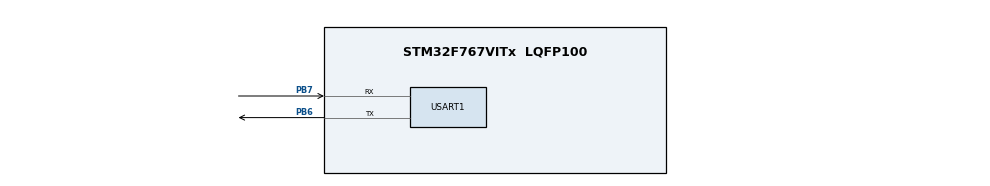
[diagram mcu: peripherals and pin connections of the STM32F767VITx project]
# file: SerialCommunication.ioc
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Dma.Request0=USART1_RX
Dma.Request1=USART1_TX
Dma.USART1_RX.0.Direction=DMA_PERIPH_TO_MEMORY
Dma.USART1_RX.0.FIFOMode=DMA_FIFOMODE_DISABLE
Dma.USART1_RX.0.Instance=DMA2_Stream5
Dma.USART1_RX.0.MemDataAlignment=DMA_MDATAALIGN_BYTE
Dma.USART1_RX.0.MemInc=DMA_MINC_ENABLE
Dma.USART1_RX.0.Mode=DMA_CIRCULAR
Dma.USART1_RX.0.PeriphDataAlignment=DMA_PDATAALIGN_BYTE
Dma.USART1_RX.0.PeriphInc=DMA_PINC_DISABLE
Dma.USART1_RX.0.Priority=DMA_PRIORITY_LOW
Dma.USART1_TX.1.Direction=DMA_MEMORY_TO_PERIPH
Dma.USART1_TX.1.FIFOMode=DMA_FIFOMODE_DISABLE
Dma.USART1_TX.1.Instance=DMA2_Stream7
Dma.USART1_TX.1.MemDataAlignment=DMA_MDATAALIGN_BYTE
Dma.USART1_TX.1.MemInc=DMA_MINC_ENABLE
Dma.USART1_TX.1.Mode=DMA_CIRCULAR
Dma.USART1_TX.1.PeriphDataAlignment=DMA_PDATAALIGN_BYTE
Dma.USART1_TX.1.PeriphInc=DMA_PINC_DISABLE
Dma.USART1_TX.1.Priority=DMA_PRIORITY_LOW
Mcu.Family=STM32F7
Mcu.Name=STM32F767VITx
Mcu.Package=LQFP100
NVIC.DMA2_Stream5_IRQn=true\:5\:0\:true\:false\:true\:false\:true
NVIC.DMA2_Stream7_IRQn=true\:5\:0\:true\:false\:true\:false\:true
NVIC.FLASH_IRQn=true\:5\:0\:true\:false\:true\:true\:true
NVIC.FPU_IRQn=true\:5\:0\:true\:false\:true\:true\:false
NVIC.PVD_IRQn=true\:5\:0\:true\:false\:true\:true\:true
NVIC.PriorityGroup=NVIC_PRIORITYGROUP_4
NVIC.RCC_IRQn=true\:5\:0\:true\:false\:true\:true\:false
NVIC.TIM7_IRQn=true\:0\:0\:true\:false\:true\:false\:true
NVIC.TimeBase=TIM7_IRQn
NVIC.TimeBaseIP=TIM7
NVIC.USART1_IRQn=true\:5\:0\:true\:false\:true\:true\:true
PA13.Mode=Serial_Wire
PA13.Signal=SYS_JTMS-SWDIO
PA14.Mode=Serial_Wire
PA14.Signal=SYS_JTCK-SWCLK
PB6.Mode=Asynchronous
PB6.Signal=USART1_TX
PB7.Mode=Asynchronous
PB7.Signal=USART1_RX
PH0/OSC_IN.Mode=HSE-External-Oscillator
PH0/OSC_IN.Signal=RCC_OSC_IN
PH1/OSC_OUT.Mode=HSE-External-Oscillator
PH1/OSC_OUT.Signal=RCC_OSC_OUT
ProjectManager.HeapSize=0x200
ProjectManager.StackSize=0x400
ProjectManager.TargetToolchain=STM32CubeIDE
RCC.AHBFreq_Value=216000000
RCC.APB1CLKDivider=RCC_HCLK_DIV4
RCC.APB1Freq_Value=54000000
RCC.APB1TimFreq_Value=108000000
RCC.APB2CLKDivider=RCC_HCLK_DIV4
RCC.APB2Freq_Value=54000000
RCC.APB2TimFreq_Value=108000000
RCC.CortexFreq_Value=216000000
RCC.HCLKFreq_Value=216000000
RCC.HSE_VALUE=25000000
RCC.HSI_VALUE=16000000
RCC.LSE_VALUE=32768
RCC.PLLM=25
RCC.PLLN=432
RCC.PLLSourceVirtual=RCC_PLLSOURCE_HSE
RCC.PWREXT_OverDrive=PWREXT_OverDrive_ACTIVATED
RCC.PWR_Regulator_Voltage_Scale=PWR_REGULATOR_VOLTAGE_SCALE1
RCC.SYSCLKFreq_VALUE=216000000
RCC.SYSCLKSource=RCC_SYSCLKSOURCE_PLLCLK
RCC.USBFreq_Value=216000000
RCC.VCOOutputFreq_Value=432000000
USART1.DMADisableonRxErrorParam=ADVFEATURE_DMA_DISABLEONRXERROR
USART1.OverrunDisableParam=ADVFEATURE_OVERRUN_DISABLE
USART1.VirtualMode-Asynchronous=VM_ASYNC
VP_SYS_VS_tim7.Mode=TIM7
board=custom

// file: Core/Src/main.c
/* USER CODE BEGIN Header */
/**
  ******************************************************************************
  * @file           : main.c
  * @brief          : Main program body
  ******************************************************************************
  * @attention
  *
  * <h2><center>&copy; Copyright (c) 2023 STMicroelectronics.
  * All rights reserved.</center></h2>
  *
  * This software component is licensed by ST under BSD 3-Clause license,
  * the "License"; You may not use this file except in compliance with the
  * License. You may obtain a copy of the License at:
  *                        opensource.org/licenses/BSD-3-Clause
  *
  ******************************************************************************
  */
/* USER CODE END Header */
#include "main.h"
#include "dma.h"
#include "usart.h"
#include "gpio.h"

/* USER CODE BEGIN Includes */
#include "mbotLinuxUsart.h"
/* USER CODE END Includes */

/* USER CODE BEGIN PV */
//测试发�?�变�??
// send the uav's position and orierntation to linux
/*double positionX_uav, positionY_uav, positionZ_uav;
double orientationX_uav, orientationY_uav, orientationZ_uav, orientationW_uav;*/

double positionX_uav = 0.4222;
double positionY_uav = 0.4222;
double positionZ_uav = 0.4222;
double orientationX_uav =  0.4222;
double orientationY_uav = 0.4222;
double orientationZ_uav = 0.4222;
double orientationW_uav = 0.5555;

/*short testSend1   =5000;
short testSend2   =2000;
short testSend3   =1000;
unsigned char testSend4 = 0x05;
*/
// receive mocap value,and reserve pose and orientaion in position and orierntation
int positionX_mocap, positionY_mocap, positionZ_nocap;
int orientationX_mocap, orientationY_mocap, orientationZ_mocap, orientationW_mocap;
//测试接收变量
/*
int testRece1     =0;
int testRece2     =0;
unsigned char testRece3 = 0x00;
*/
/* USER CODE END PV */

void SystemClock_Config(void);

int main(void)
{

  /* MCU Configuration--------------------------------------------------------*/

  /* Reset of all peripherals, Initializes the Flash interface and the Systick. */
  HAL_Init();

  /* Configure the system clock */
  SystemClock_Config();

  /* Initialize all configured peripherals */
  MX_GPIO_Init();
  MX_DMA_Init();
  MX_USART1_UART_Init();

  /* Infinite loop */
  while (1)
  {
		//将需要发送到ROS的数据，从该函数发出，前三个数据范围（-32768 - +32767），第四个数据的范围(0 - 255)
		usartSendData( positionX_uav, positionY_uav, positionZ_uav,
    orientationX_uav, orientationY_uav, orientationZ_uav, orientationW_uav);
		//必须的延时
		HAL_Delay(13);
  }
}

void SystemClock_Config(void)
{
  LL_FLASH_SetLatency(LL_FLASH_LATENCY_7);
  while(LL_FLASH_GetLatency()!= LL_FLASH_LATENCY_7)
  {
  }
  LL_PWR_SetRegulVoltageScaling(LL_PWR_REGU_VOLTAGE_SCALE1);
  LL_PWR_EnableOverDriveMode();
  LL_RCC_HSE_Enable();

   /* Wait till HSE is ready */
  while(LL_RCC_HSE_IsReady() != 1)
  {

  }
  LL_RCC_PLL_ConfigDomain_SYS(LL_RCC_PLLSOURCE_HSE, LL_RCC_PLLM_DIV_25, 432, LL_RCC_PLLP_DIV_2);
  LL_RCC_PLL_Enable();

   /* Wait till PLL is ready */
  while(LL_RCC_PLL_IsReady() != 1)
  {

  }
  LL_RCC_SetAHBPrescaler(LL_RCC_SYSCLK_DIV_1);
  LL_RCC_SetAPB1Prescaler(LL_RCC_APB1_DIV_4);
  LL_RCC_SetAPB2Prescaler(LL_RCC_APB2_DIV_4);
  LL_RCC_SetSysClkSource(LL_RCC_SYS_CLKSOURCE_PLL);

   /* Wait till System clock is ready */
  while(LL_RCC_GetSysClkSource() != LL_RCC_SYS_CLKSOURCE_STATUS_PLL)
  {

  }
  LL_SetSystemCoreClock(216000000);

   /* Update the time base */
  if (HAL_InitTick (TICK_INT_PRIORITY) != HAL_OK)
  {
    Error_Handler();
  }
  LL_RCC_SetUSARTClockSource(LL_RCC_USART1_CLKSOURCE_PCLK2);
}

 /**
  * @brief  Period elapsed callback in non blocking mode
  * @note   This function is called  when TIM7 interrupt took place, inside
  * HAL_TIM_IRQHandler(). It makes a direct call to HAL_IncTick() to increment
  * a global variable "uwTick" used as application time base.
  * @param  htim : TIM handle
  * @retval None
  */
void HAL_TIM_PeriodElapsedCallback(TIM_HandleTypeDef *htim)
{
  if (htim->Instance == TIM7) {
    HAL_IncTick();
  }
}

void Error_Handler(void)
{
  /* USER CODE BEGIN Error_Handler_Debug */
  /* User can add his own implementation to report the HAL error return state */
//  __disable_irq();
//  while (1)
//  {
//  }
  /* USER CODE END Error_Handler_Debug */
}
void USART1_IRQHandler(void)
{
	if(LL_USART_IsActiveFlag_IDLE(USART1))
	{
		LL_USART_ClearFlag_IDLE(USART1);
		usartReceiveOneData(&positionX_mocap, &positionY_mocap, &positionZ_nocap,
                &orientationX_mocap, &orientationY_mocap, &orientationZ_mocap, &orientationW_mocap);
//		LL_DMA_DisableStream(DMA2,LL_DMA_STREAM_5);
//		LL_DMA_ClearFlag_DME5(DMA2);
//		LL_DMA_ClearFlag_HT5(DMA2);
//		LL_DMA_ClearFlag_TC5(DMA2);
//		LL_DMA_ClearFlag_TE5(DMA2);
//		LL_DMA_ClearFlag_FE5(DMA2);
//		LL_DMA_SetDataLength(DMA2, LL_DMA_STREAM_5, RX_LEN);
//		LL_DMA_EnableStream(DMA2, LL_DMA_STREAM_5);
	}
}

/************************ (C) COPYRIGHT STMicroelectronics *****END OF FILE****/
